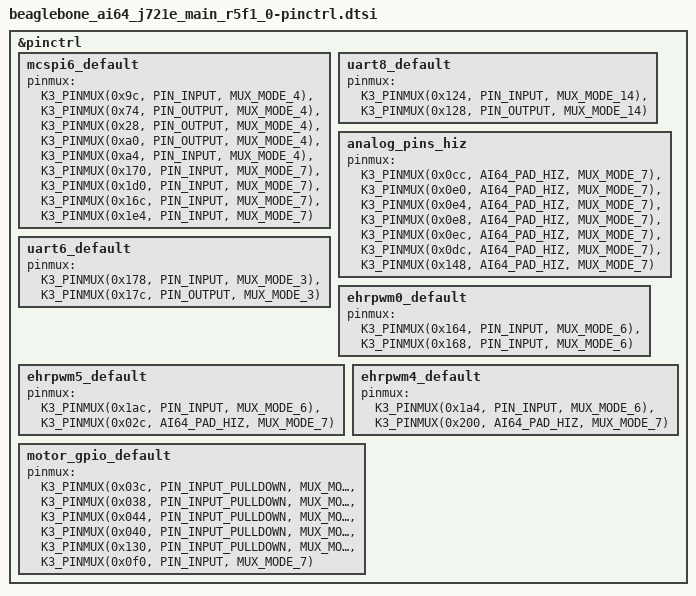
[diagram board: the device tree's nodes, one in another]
/*
 * Copyright (c) 2026 The Perotheia authors
 *
 * SPDX-License-Identifier: Apache-2.0
 */

#include <zephyr/dt-bindings/pinctrl/ti-k3-pinctrl.h>

/* pad off: no receiver, no pull, output driver disabled (PADCONFIG TX_DIS) */
#define AI64_PAD_HIZ (INPUT_DISABLE | PULL_DISABLE | (1 << 21))

&pinctrl {
	/*
	 * MCSPI6 on the P9 header, two chip selects (as BeagleBoard's
	 * k3-j721e-beagleboneai64-spi-mcspi6-cs0-cs1 overlay). Each of these
	 * header pins is also wired to a second SoC pad: those are parked as
	 * GPIO inputs (high impedance) so that they do not fight the bus.
	 */
	mcspi6_default: mcspi6_default {
		pinmux = <K3_PINMUX(0x9c, PIN_INPUT, MUX_MODE_4)>,	/* P9_22a SPI6_CLK (receiver on: the
								 * module clocks RX from the pad)
								 */
			 <K3_PINMUX(0x74, PIN_OUTPUT, MUX_MODE_4)>,	/* P9_17a SPI6_CS0 */
			 <K3_PINMUX(0x28, PIN_OUTPUT, MUX_MODE_4)>,	/* P9_23  SPI6_CS1 */
			 <K3_PINMUX(0xa0, PIN_OUTPUT, MUX_MODE_4)>,	/* P9_21a SPI6_D0 (MOSI) */
			 <K3_PINMUX(0xa4, PIN_INPUT, MUX_MODE_4)>,	/* P9_18a SPI6_D1 (MISO) */
			 <K3_PINMUX(0x170, PIN_INPUT, MUX_MODE_7)>,	/* P9_22b parked */
			 <K3_PINMUX(0x1d0, PIN_INPUT, MUX_MODE_7)>,	/* P9_17b parked */
			 <K3_PINMUX(0x16c, PIN_INPUT, MUX_MODE_7)>,	/* P9_21b parked */
			 <K3_PINMUX(0x1e4, PIN_INPUT, MUX_MODE_7)>;	/* P9_18b parked */
	};

	/* UART8 on P8_28 (RX) / P8_29 (TX), mux mode 14 */
	uart8_default: uart8_default {
		pinmux = <K3_PINMUX(0x124, PIN_INPUT, MUX_MODE_14)>,	/* P8_28 UART8_RXD */
			 <K3_PINMUX(0x128, PIN_OUTPUT, MUX_MODE_14)>;	/* P8_29 UART8_TXD */
	};

	/*
	 * P9_33 and P9_35..P9_40 are the analog inputs (MCU_ADC0, a 1.8 V
	 * domain). Each is shorted on the header to a 3.3 V digital ball of
	 * the MAIN domain, which must never drive: receiver, pulls and output
	 * driver (TX_DIS, bit 21) off, GPIO mode.
	 */
	analog_pins_hiz: analog_pins_hiz {
		pinmux = <K3_PINMUX(0x0cc, AI64_PAD_HIZ, MUX_MODE_7)>,	/* P9_33 AC28 */
			 <K3_PINMUX(0x0e0, AI64_PAD_HIZ, MUX_MODE_7)>,	/* P9_35 AH27 */
			 <K3_PINMUX(0x0e4, AI64_PAD_HIZ, MUX_MODE_7)>,	/* P9_36 AH29 */
			 <K3_PINMUX(0x0e8, AI64_PAD_HIZ, MUX_MODE_7)>,	/* P9_37 AG28 */
			 <K3_PINMUX(0x0ec, AI64_PAD_HIZ, MUX_MODE_7)>,	/* P9_38 AG27 */
			 <K3_PINMUX(0x0dc, AI64_PAD_HIZ, MUX_MODE_7)>,	/* P9_39 AJ28 */
			 <K3_PINMUX(0x148, AI64_PAD_HIZ, MUX_MODE_7)>;	/* P9_40 AA26 */
	};

	/* UART6 on P9_14 (RX) / P9_16 (TX), mux mode 3 */
	uart6_default: uart6_default {
		pinmux = <K3_PINMUX(0x178, PIN_INPUT, MUX_MODE_3)>,	/* P9_14 UART6_RXD */
			 <K3_PINMUX(0x17c, PIN_OUTPUT, MUX_MODE_3)>;	/* P9_16 UART6_TXD */
	};

	/*
	 * Four PWM outputs free of the SPI6 / UART4 / UART6 pins, mux mode 6.
	 * The receivers stay on (PIN_INPUT) so the level can be read back
	 * through the GPIO input registers.
	 */
	ehrpwm0_default: ehrpwm0_default {
		pinmux = <K3_PINMUX(0x164, PIN_INPUT, MUX_MODE_6)>,	/* P8_19 EHRPWM0_A */
			 <K3_PINMUX(0x168, PIN_INPUT, MUX_MODE_6)>;	/* P8_13 EHRPWM0_B */
	};

	/* P8_37 has two balls: EHRPWM5_A on Y27, AD21 off */
	ehrpwm5_default: ehrpwm5_default {
		pinmux = <K3_PINMUX(0x1ac, PIN_INPUT, MUX_MODE_6)>,	/* P8_37 EHRPWM5_A (Y27) */
			 <K3_PINMUX(0x02c, AI64_PAD_HIZ, MUX_MODE_7)>;	/* P8_37 AD21 off */
	};

	/* P9_25 has two balls: EHRPWM4_B on W26, AC4 off */
	ehrpwm4_default: ehrpwm4_default {
		pinmux = <K3_PINMUX(0x1a4, PIN_INPUT, MUX_MODE_6)>,	/* P9_25 EHRPWM4_B (W26) */
			 <K3_PINMUX(0x200, AI64_PAD_HIZ, MUX_MODE_7)>;	/* P9_25 AC4 off */
	};

	/*
	 * Motor bridge control on GPIO2 (pads of GPIO0_n), mux mode 7. The
	 * outputs are pulled down (the board adds 10k pull-downs): bridges
	 * disabled, brakes applied and the output stage disarmed while the
	 * pins are inputs (reset, core stopped).
	 *   EN_L P8_07 (15), EN_R P8_08 (14): bridge enables
	 *   BRAKE_L P8_09 (17), BRAKE_R P8_10 (16): high = brake released
	 *   DRV_ARM P8_14 (75): high = level-shifter outputs enabled
	 *   ESTOP_SENSE P8_12 (59): input, external pull-up, low = bus live
	 */
	motor_gpio_default: motor_gpio_default {
		pinmux = <K3_PINMUX(0x03c, PIN_INPUT_PULLDOWN, MUX_MODE_7)>,	/* P8_07 EN_L */
			 <K3_PINMUX(0x038, PIN_INPUT_PULLDOWN, MUX_MODE_7)>,	/* P8_08 EN_R */
			 <K3_PINMUX(0x044, PIN_INPUT_PULLDOWN, MUX_MODE_7)>,	/* P8_09 BRAKE_L */
			 <K3_PINMUX(0x040, PIN_INPUT_PULLDOWN, MUX_MODE_7)>,	/* P8_10 BRAKE_R */
			 <K3_PINMUX(0x130, PIN_INPUT_PULLDOWN, MUX_MODE_7)>,	/* P8_14 DRV_ARM */
			 <K3_PINMUX(0x0f0, PIN_INPUT, MUX_MODE_7)>;		/* P8_12 ESTOP_SENSE */
	};
};
